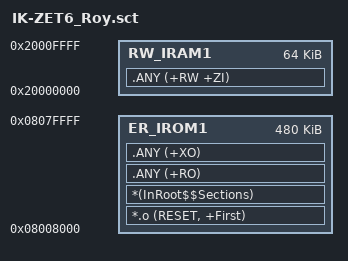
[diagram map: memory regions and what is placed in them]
; *************************************************************
; *** Scatter-Loading Description File generated by uVision ***
; *************************************************************

LR_IROM1 0x08008000 0x00078000  {    ; load region size_region
  ER_IROM1 0x08008000 0x00078000  {  ; load address = execution address
   *.o (RESET, +First)
   *(InRoot$$Sections)
   .ANY (+RO)
   .ANY (+XO)
  }
  RW_IRAM1 0x20000000 0x00010000  {  ; RW data
   .ANY (+RW +ZI)
  }
}

;LR_ROM1 0xC0000000 0x01000000  {
;  ER_ROM1 0xC0000000 0x01000000  {  ; load address = execution address
    ; *(.EXFLASH)
	; testfonts.o (+RO)
;  }
;}

;LR_ROM1 0xC0004000 0x00FFC000  {
  ;ER_ROM1 0xC0004000 0x00FFC000  {  ; load address = execution address
    ;*(.EXFLASH)
	 ;testfonts.o (+RO)
  ;}
;}
